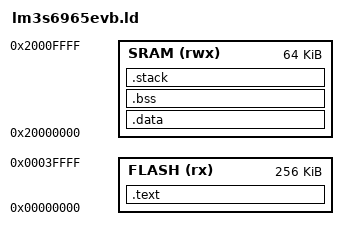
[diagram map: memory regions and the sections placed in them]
MEMORY
{
    FLASH (rx) : ORIGIN = 0x00000000, LENGTH = 256K
    SRAM (rwx) : ORIGIN = 0x20000000, LENGTH = 64K
}

ENTRY(Reset_Handler)

SECTIONS
{
    .text :
    {
        KEEP(*(.isr_vector))
        *(.text*)
        *(.rodata*)
        *(.init)
        *(.fini)
        *(.ARM.exidx*)
        . = ALIGN(4);
        _etext = .;
    } > FLASH

    .data : AT(_etext)
    {
        . = ALIGN(4);
        _sdata = .;
        *(.data*)
        . = ALIGN(4);
        _edata = .;
    } > SRAM

    .bss :
    {
        . = ALIGN(4);
        _sbss = .;
        *(.bss*)
        *(COMMON)
        . = ALIGN(4);
        _ebss = .;
    } > SRAM

    /* Allocate space for main stack and ensure 8-byte alignment */
    .stack (NOLOAD) :
    {
        . = ALIGN(8);
        . = . + 2048; /* 2KB main stack size */
        . = ALIGN(8);
        _estack = .;
    } > SRAM

    _end = .;
    end = .;
}
